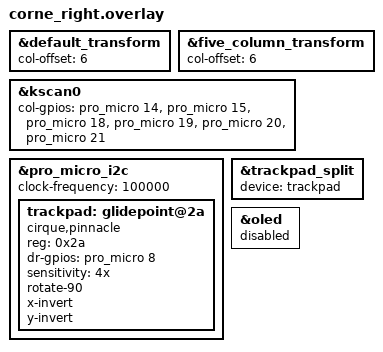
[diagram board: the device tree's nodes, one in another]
#include "corne_trackpad.dtsi"

&default_transform {
    col-offset = <6>;
};

&five_column_transform {
    col-offset = <6>;
};

&kscan0 {
    col-gpios
        = <&pro_micro 14 GPIO_ACTIVE_HIGH>
        , <&pro_micro 15 GPIO_ACTIVE_HIGH>
        , <&pro_micro 18 GPIO_ACTIVE_HIGH>
        , <&pro_micro 19 GPIO_ACTIVE_HIGH>
        , <&pro_micro 20 GPIO_ACTIVE_HIGH>
        , <&pro_micro 21 GPIO_ACTIVE_HIGH>
        ;
};

&pro_micro_i2c {
    status = "okay";
    clock-frequency = <100000>;

    trackpad: glidepoint@2a {
        compatible = "cirque,pinnacle";
        reg = <0x2a>;
        status = "okay";
        /* Wire trackpad FFC pin 4 (DR) to PCB label B4/8 on the right half. */
        dr-gpios = <&pro_micro 8 (GPIO_ACTIVE_HIGH)>;
        sensitivity = "4x";
        rotate-90;
        x-invert;
        y-invert;
    };
};

&trackpad_split {
    device = <&trackpad>;
};

&oled {
    status = "disabled";
};
